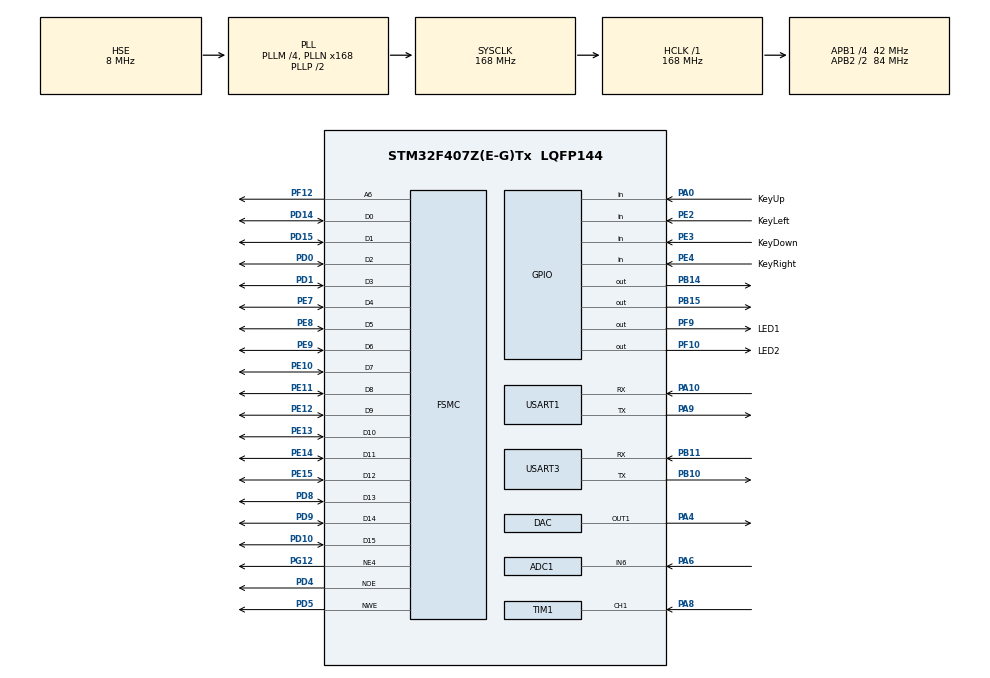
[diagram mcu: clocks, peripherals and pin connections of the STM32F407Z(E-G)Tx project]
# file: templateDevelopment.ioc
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ADC1.Channel-0\#ChannelRegularConversion=ADC_CHANNEL_6
ADC1.DMAContinuousRequests=DISABLE
ADC1.ExternalTrigConv=ADC_EXTERNALTRIGCONV_T3_TRGO
ADC1.NbrOfConversionFlag=1
ADC1.Rank-0\#ChannelRegularConversion=1
ADC1.SamplingTime-0\#ChannelRegularConversion=ADC_SAMPLETIME_3CYCLES
ADC1.master=1
Dma.ADC1.2.Direction=DMA_PERIPH_TO_MEMORY
Dma.ADC1.2.FIFOMode=DMA_FIFOMODE_DISABLE
Dma.ADC1.2.Instance=DMA2_Stream0
Dma.ADC1.2.MemDataAlignment=DMA_MDATAALIGN_HALFWORD
Dma.ADC1.2.MemInc=DMA_MINC_ENABLE
Dma.ADC1.2.Mode=DMA_CIRCULAR
Dma.ADC1.2.PeriphDataAlignment=DMA_PDATAALIGN_HALFWORD
Dma.ADC1.2.PeriphInc=DMA_PINC_DISABLE
Dma.ADC1.2.Priority=DMA_PRIORITY_HIGH
Dma.Request0=USART1_RX
Dma.Request1=USART1_TX
Dma.Request2=ADC1
Dma.Request3=USART3_RX
Dma.Request4=USART3_TX
Dma.USART1_RX.0.Direction=DMA_PERIPH_TO_MEMORY
Dma.USART1_RX.0.FIFOMode=DMA_FIFOMODE_DISABLE
Dma.USART1_RX.0.Instance=DMA2_Stream2
Dma.USART1_RX.0.MemDataAlignment=DMA_MDATAALIGN_BYTE
Dma.USART1_RX.0.MemInc=DMA_MINC_ENABLE
Dma.USART1_RX.0.Mode=DMA_NORMAL
Dma.USART1_RX.0.PeriphDataAlignment=DMA_PDATAALIGN_BYTE
Dma.USART1_RX.0.PeriphInc=DMA_PINC_DISABLE
Dma.USART1_RX.0.Priority=DMA_PRIORITY_LOW
Dma.USART1_TX.1.Direction=DMA_MEMORY_TO_PERIPH
Dma.USART1_TX.1.FIFOMode=DMA_FIFOMODE_DISABLE
Dma.USART1_TX.1.Instance=DMA2_Stream7
Dma.USART1_TX.1.MemDataAlignment=DMA_MDATAALIGN_BYTE
Dma.USART1_TX.1.MemInc=DMA_MINC_ENABLE
Dma.USART1_TX.1.Mode=DMA_NORMAL
Dma.USART1_TX.1.PeriphDataAlignment=DMA_PDATAALIGN_BYTE
Dma.USART1_TX.1.PeriphInc=DMA_PINC_DISABLE
Dma.USART1_TX.1.Priority=DMA_PRIORITY_LOW
Dma.USART3_RX.3.Direction=DMA_PERIPH_TO_MEMORY
Dma.USART3_RX.3.FIFOMode=DMA_FIFOMODE_DISABLE
Dma.USART3_RX.3.Instance=DMA1_Stream1
Dma.USART3_RX.3.MemDataAlignment=DMA_MDATAALIGN_BYTE
Dma.USART3_RX.3.MemInc=DMA_MINC_ENABLE
Dma.USART3_RX.3.Mode=DMA_CIRCULAR
Dma.USART3_RX.3.PeriphDataAlignment=DMA_PDATAALIGN_BYTE
Dma.USART3_RX.3.PeriphInc=DMA_PINC_DISABLE
Dma.USART3_RX.3.Priority=DMA_PRIORITY_LOW
Dma.USART3_TX.4.Direction=DMA_MEMORY_TO_PERIPH
Dma.USART3_TX.4.FIFOMode=DMA_FIFOMODE_DISABLE
Dma.USART3_TX.4.Instance=DMA1_Stream3
Dma.USART3_TX.4.MemDataAlignment=DMA_MDATAALIGN_BYTE
Dma.USART3_TX.4.MemInc=DMA_MINC_ENABLE
Dma.USART3_TX.4.Mode=DMA_CIRCULAR
Dma.USART3_TX.4.PeriphDataAlignment=DMA_PDATAALIGN_BYTE
Dma.USART3_TX.4.PeriphInc=DMA_PINC_DISABLE
Dma.USART3_TX.4.Priority=DMA_PRIORITY_LOW
FSMC.AddressSetupTime1=15
FSMC.BusTurnAroundDuration1=0
FSMC.DataSetupTime1=60
FSMC.ExtendedAddressSetupTime1=9
FSMC.ExtendedBusTurnAroundDuration1=0
FSMC.ExtendedDataSetupTime1=8
FSMC.ExtendedMode1=FSMC_EXTENDED_MODE_ENABLE
Mcu.Family=STM32F4
Mcu.Name=STM32F407Z(E-G)Tx
Mcu.Package=LQFP144
NVIC.ADC_IRQn=true\:0\:0\:false\:false\:true\:true\:true\:true
NVIC.DMA1_Stream1_IRQn=true\:0\:0\:false\:false\:true\:false\:true\:true
NVIC.DMA1_Stream3_IRQn=true\:0\:0\:false\:false\:true\:false\:true\:true
NVIC.DMA2_Stream0_IRQn=true\:0\:0\:false\:false\:true\:false\:true\:true
NVIC.DMA2_Stream2_IRQn=true\:0\:0\:false\:false\:true\:false\:true\:true
NVIC.DMA2_Stream7_IRQn=true\:0\:0\:false\:false\:true\:false\:true\:true
NVIC.PriorityGroup=NVIC_PRIORITYGROUP_4
NVIC.TIM1_CC_IRQn=true\:0\:0\:false\:false\:true\:true\:true\:true
NVIC.TIM1_UP_TIM10_IRQn=true\:0\:0\:false\:false\:true\:true\:true\:true
NVIC.USART1_IRQn=true\:0\:0\:false\:false\:true\:true\:true\:true
NVIC.USART3_IRQn=true\:0\:0\:false\:false\:true\:true\:true\:true
PA0-WKUP.GPIO_Label=KeyUp
PA0-WKUP.GPIO_PuPd=GPIO_PULLDOWN
PA0-WKUP.Signal=GPIO_Input
PA10.Mode=Asynchronous
PA10.Signal=USART1_RX
PA4.Signal=COMP_DAC1_group
PA6.Signal=SharedAnalog_PA6
PA8.Signal=S_TIM1_CH1
PA9.Mode=Asynchronous
PA9.Signal=USART1_TX
PB10.Mode=Asynchronous
PB10.Signal=USART3_TX
PB11.Mode=Asynchronous
PB11.Signal=USART3_RX
PB14.Signal=GPIO_Output
PB15.GPIO_ModeDefaultOutputPP=GPIO_MODE_OUTPUT_PP
PB15.GPIO_PuPd=GPIO_PULLUP
PB15.Signal=GPIO_Output
PC14-OSC32_IN.Mode=LSE-External-Oscillator
PC14-OSC32_IN.Signal=RCC_OSC32_IN
PC15-OSC32_OUT.Mode=LSE-External-Oscillator
PC15-OSC32_OUT.Signal=RCC_OSC32_OUT
PD0.Signal=FSMC_D2_DA2
PD1.Signal=FSMC_D3_DA3
PD10.Signal=FSMC_D15_DA15
PD14.Signal=FSMC_D0_DA0
PD15.Signal=FSMC_D1_DA1
PD4.Signal=FSMC_NOE
PD5.Signal=FSMC_NWE
PD8.Signal=FSMC_D13_DA13
PD9.Signal=FSMC_D14_DA14
PE10.Signal=FSMC_D7_DA7
PE11.Signal=FSMC_D8_DA8
PE12.Signal=FSMC_D9_DA9
PE13.Signal=FSMC_D10_DA10
PE14.Signal=FSMC_D11_DA11
PE15.Signal=FSMC_D12_DA12
PE2.GPIO_Label=KeyLeft
PE2.GPIO_PuPd=GPIO_PULLUP
PE2.Signal=GPIO_Input
PE3.GPIO_Label=KeyDown
PE3.GPIO_PuPd=GPIO_PULLUP
PE3.Signal=GPIO_Input
PE4.GPIO_Label=KeyRight
PE4.GPIO_PuPd=GPIO_PULLUP
PE4.Signal=GPIO_Input
PE7.Signal=FSMC_D4_DA4
PE8.Signal=FSMC_D5_DA5
PE9.Signal=FSMC_D6_DA6
PF10.GPIO_Label=LED2
PF10.Signal=GPIO_Output
PF12.Signal=FSMC_A6
PF9.GPIO_Label=LED1
PF9.Signal=GPIO_Output
PG12.Mode=NorPsramChipSelect4_1
PG12.Signal=FSMC_NE4
PH0-OSC_IN.Mode=HSE-External-Oscillator
PH0-OSC_IN.Signal=RCC_OSC_IN
PH1-OSC_OUT.Mode=HSE-External-Oscillator
PH1-OSC_OUT.Signal=RCC_OSC_OUT
ProjectManager.HeapSize=0x200
ProjectManager.StackSize=0x400
ProjectManager.TargetToolchain=STM32CubeIDE
RCC.48MHZClocksFreq_Value=84000000
RCC.AHBFreq_Value=168000000
RCC.APB1CLKDivider=RCC_HCLK_DIV4
RCC.APB1Freq_Value=42000000
RCC.APB1TimFreq_Value=84000000
RCC.APB2CLKDivider=RCC_HCLK_DIV2
RCC.APB2Freq_Value=84000000
RCC.APB2TimFreq_Value=168000000
RCC.CortexFreq_Value=168000000
RCC.HCLKFreq_Value=168000000
RCC.HSE_VALUE=8000000
RCC.HSI_VALUE=16000000
RCC.PLLM=4
RCC.PLLN=168
RCC.PLLSourceVirtual=RCC_PLLSOURCE_HSE
RCC.SYSCLKFreq_VALUE=168000000
RCC.SYSCLKSource=RCC_SYSCLKSOURCE_PLLCLK
RCC.VCOOutputFreq_Value=336000000
SH.COMP_DAC1_group.0=DAC_OUT1,DAC_OUT1
SH.FSMC_A6.0=FSMC_A6,A6_1
SH.FSMC_D0_DA0.0=FSMC_D0,16b-d1
SH.FSMC_D10_DA10.0=FSMC_D10,16b-d1
SH.FSMC_D11_DA11.0=FSMC_D11,16b-d1
SH.FSMC_D12_DA12.0=FSMC_D12,16b-d1
SH.FSMC_D13_DA13.0=FSMC_D13,16b-d1
SH.FSMC_D14_DA14.0=FSMC_D14,16b-d1
SH.FSMC_D15_DA15.0=FSMC_D15,16b-d1
SH.FSMC_D1_DA1.0=FSMC_D1,16b-d1
SH.FSMC_D2_DA2.0=FSMC_D2,16b-d1
SH.FSMC_D3_DA3.0=FSMC_D3,16b-d1
SH.FSMC_D4_DA4.0=FSMC_D4,16b-d1
SH.FSMC_D5_DA5.0=FSMC_D5,16b-d1
SH.FSMC_D6_DA6.0=FSMC_D6,16b-d1
SH.FSMC_D7_DA7.0=FSMC_D7,16b-d1
SH.FSMC_D8_DA8.0=FSMC_D8,16b-d1
SH.FSMC_D9_DA9.0=FSMC_D9,16b-d1
SH.FSMC_NOE.0=FSMC_NOE,Lcd1
SH.FSMC_NWE.0=FSMC_NWE,Lcd1
SH.S_TIM1_CH1.0=TIM1_CH1,Input_Capture1_from_TI1
SH.SharedAnalog_PA6.0=GPIO_Analog
SH.SharedAnalog_PA6.1=ADC1_IN6,IN6
STMicroelectronics.X-CUBE-ALGOBUILD.1.3.0.LibraryCcDSPOoLibraryJjDSPOoLibrary=true
TIM1.Channel-Input_Capture1_from_TI1=TIM_CHANNEL_1
TIM1.Prescaler=168-1
TIM3.AutoReloadPreload=TIM_AUTORELOAD_PRELOAD_ENABLE
TIM3.Period=10-1
TIM3.Prescaler=84-1
TIM3.TIM_MasterOutputTrigger=TIM_TRGO_UPDATE
USART1.VirtualMode=VM_ASYNC
USART3.VirtualMode=VM_ASYNC
VP_STMicroelectronics.X-CUBE-ALGOBUILD_VS_DSPOoLibraryJjLibrary_1.3.0_1.3.0.Mode=DSPOoLibraryJjLibrary
VP_TIM1_VS_ClockSourceINT.Mode=Internal
VP_TIM3_VS_ClockSourceINT.Mode=Internal
board=custom

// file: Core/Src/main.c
/* USER CODE BEGIN Header */
/**
  ******************************************************************************
  * @file           : main.c
  * @brief          : Main program body
  ******************************************************************************
  * @attention
  *
  * Copyright (c) 2023 STMicroelectronics.
  * All rights reserved.
  *
  * This software is licensed under terms that can be found in the LICENSE file
  * in the root directory of this software component.
  * If no LICENSE file comes with this software, it is provided AS-IS.
  *
  ******************************************************************************
  */
/* USER CODE END Header */
#include "main.h"
#include "adc.h"
#include "dac.h"
#include "dma.h"
#include "tim.h"
#include "usart.h"
#include "gpio.h"
#include "fsmc.h"

/* USER CODE BEGIN Includes */
#include "Myapplication.h"
#include "seriall_Port.h"
#include "myAdc.h"
#include "string.h"

/* USER CODE END Includes */

/* USER CODE BEGIN PM */
#define SIZE 1024
/* USER CODE END PM */

void SystemClock_Config(void);

int main(void)
{

  /* MCU Configuration--------------------------------------------------------*/

  /* Reset of all peripherals, Initializes the Flash interface and the Systick. */
  HAL_Init();

  /* Configure the system clock */
  SystemClock_Config();

  /* Initialize all configured peripherals */
  MX_GPIO_Init();
  MX_DMA_Init();
  MX_USART1_UART_Init();
  MX_FSMC_Init();
  MX_ADC1_Init();
  MX_TIM3_Init();
  MX_DAC_Init();
  MX_USART3_UART_Init();
  MX_TIM1_Init();
  /* USER CODE BEGIN 2 */

    //TFTLCD_Init();
    Mymain();

  /* USER CODE END 2 */

  /* Infinite loop */
  /* USER CODE BEGIN WHILE */
  while (1)
  {
      //SendReceive(&huart1);
    /* USER CODE END WHILE */

  }
}

void SystemClock_Config(void)
{
  RCC_OscInitTypeDef RCC_OscInitStruct = {0};
  RCC_ClkInitTypeDef RCC_ClkInitStruct = {0};

  /** Configure the main internal regulator output voltage
  */
  __HAL_RCC_PWR_CLK_ENABLE();
  __HAL_PWR_VOLTAGESCALING_CONFIG(PWR_REGULATOR_VOLTAGE_SCALE1);

  /** Initializes the RCC Oscillators according to the specified parameters
  * in the RCC_OscInitTypeDef structure.
  */
  RCC_OscInitStruct.OscillatorType = RCC_OSCILLATORTYPE_HSE;
  RCC_OscInitStruct.HSEState = RCC_HSE_ON;
  RCC_OscInitStruct.PLL.PLLState = RCC_PLL_ON;
  RCC_OscInitStruct.PLL.PLLSource = RCC_PLLSOURCE_HSE;
  RCC_OscInitStruct.PLL.PLLM = 4;
  RCC_OscInitStruct.PLL.PLLN = 168;
  RCC_OscInitStruct.PLL.PLLP = RCC_PLLP_DIV2;
  RCC_OscInitStruct.PLL.PLLQ = 4;
  if (HAL_RCC_OscConfig(&RCC_OscInitStruct) != HAL_OK)
  {
    Error_Handler();
  }

  /** Initializes the CPU, AHB and APB buses clocks
  */
  RCC_ClkInitStruct.ClockType = RCC_CLOCKTYPE_HCLK|RCC_CLOCKTYPE_SYSCLK
                              |RCC_CLOCKTYPE_PCLK1|RCC_CLOCKTYPE_PCLK2;
  RCC_ClkInitStruct.SYSCLKSource = RCC_SYSCLKSOURCE_PLLCLK;
  RCC_ClkInitStruct.AHBCLKDivider = RCC_SYSCLK_DIV1;
  RCC_ClkInitStruct.APB1CLKDivider = RCC_HCLK_DIV4;
  RCC_ClkInitStruct.APB2CLKDivider = RCC_HCLK_DIV2;

  if (HAL_RCC_ClockConfig(&RCC_ClkInitStruct, FLASH_LATENCY_5) != HAL_OK)
  {
    Error_Handler();
  }
}

void Error_Handler(void)
{
  __disable_irq();
  while (1)
  {
  }
}
